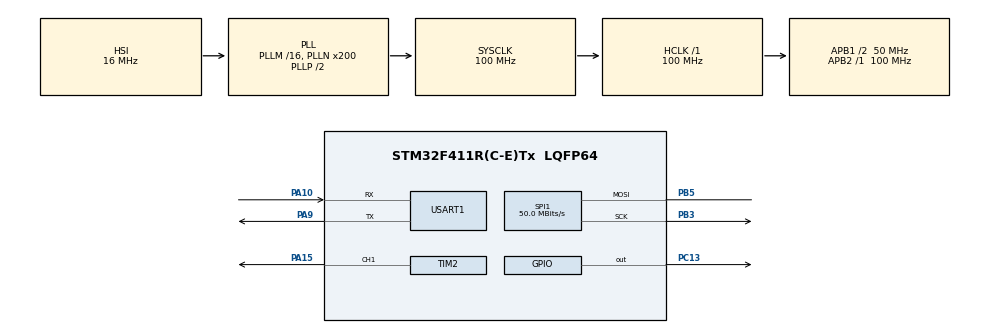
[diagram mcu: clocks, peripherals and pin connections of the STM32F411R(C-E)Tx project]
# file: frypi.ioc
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Dma.Request0=SPI1_TX
Dma.SPI1_TX.0.Direction=DMA_MEMORY_TO_PERIPH
Dma.SPI1_TX.0.FIFOMode=DMA_FIFOMODE_DISABLE
Dma.SPI1_TX.0.Instance=DMA2_Stream2
Dma.SPI1_TX.0.MemDataAlignment=DMA_MDATAALIGN_HALFWORD
Dma.SPI1_TX.0.MemInc=DMA_MINC_ENABLE
Dma.SPI1_TX.0.Mode=DMA_NORMAL
Dma.SPI1_TX.0.PeriphDataAlignment=DMA_PDATAALIGN_HALFWORD
Dma.SPI1_TX.0.PeriphInc=DMA_PINC_DISABLE
Dma.SPI1_TX.0.Priority=DMA_PRIORITY_LOW
FREERTOS.Tasks01=defaultTask,24,128,StartDefaultTask,Default,NULL,Dynamic,NULL,NULL;LED_Task,8,128,LED_TaskFunc,Default,NULL,Static,LED_TaskBuffer,LED_TaskControlBlock
FREERTOS.configUSE_TICK_HOOK=1
Mcu.Family=STM32F4
Mcu.Name=STM32F411R(C-E)Tx
Mcu.Package=LQFP64
NVIC.DMA2_Stream2_IRQn=true\:5\:0\:false\:false\:true\:true\:false\:true\:true
NVIC.PriorityGroup=NVIC_PRIORITYGROUP_4
NVIC.TIM1_TRG_COM_TIM11_IRQn=true\:15\:0\:false\:false\:true\:false\:false\:true\:true
NVIC.TimeBase=TIM1_TRG_COM_TIM11_IRQn
NVIC.TimeBaseIP=TIM11
PA10.Mode=Asynchronous
PA10.Signal=USART1_RX
PA13.Mode=Serial_Wire
PA13.Signal=SYS_JTMS-SWDIO
PA14.Mode=Serial_Wire
PA14.Signal=SYS_JTCK-SWCLK
PA15.Signal=S_TIM2_CH1_ETR
PA9.Mode=Asynchronous
PA9.Signal=USART1_TX
PB3.Mode=Simplex_Bidirectional_Master
PB3.Signal=SPI1_SCK
PB5.Mode=Simplex_Bidirectional_Master
PB5.Signal=SPI1_MOSI
PC13-ANTI_TAMP.Signal=GPIO_Output
ProjectManager.HeapSize=0x200
ProjectManager.StackSize=0x400
ProjectManager.TargetToolchain=CMake
RCC.48MHZClocksFreq_Value=50000000
RCC.AHBFreq_Value=100000000
RCC.APB1CLKDivider=RCC_HCLK_DIV2
RCC.APB1Freq_Value=50000000
RCC.APB1TimFreq_Value=100000000
RCC.APB2Freq_Value=100000000
RCC.APB2TimFreq_Value=100000000
RCC.CortexFreq_Value=100000000
RCC.HCLKFreq_Value=100000000
RCC.HSE_VALUE=25000000
RCC.HSI_VALUE=16000000
RCC.LSE_VALUE=32768
RCC.PLLN=200
RCC.SYSCLKFreq_VALUE=100000000
RCC.SYSCLKSource=RCC_SYSCLKSOURCE_PLLCLK
RCC.VCOOutputFreq_Value=200000000
SH.S_TIM2_CH1_ETR.0=TIM2_CH1,PWM Generation1 CH1
SPI1.CLKPhase=SPI_PHASE_2EDGE
SPI1.CLKPolarity=SPI_POLARITY_HIGH
SPI1.CalculateBaudRate=50.0 MBits/s
SPI1.Direction=SPI_DIRECTION_1LINE
SPI1.Mode=SPI_MODE_MASTER
SPI1.VirtualType=VM_MASTER
TIM2.Channel-PWM\ Generation1\ CH1=TIM_CHANNEL_1
TIM2.Period=300
TIM2.Prescaler=99
USART1.VirtualMode=VM_ASYNC
VP_FREERTOS_VS_CMSIS_V2.Mode=CMSIS_V2
VP_SYS_VS_tim11.Mode=TIM11
board=custom

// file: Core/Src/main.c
/* USER CODE BEGIN Header */
/**
  ******************************************************************************
  * @file           : main.c
  * @brief          : Main program body
  ******************************************************************************
  * @attention
  *
  * Copyright (c) 2026 STMicroelectronics.
  * All rights reserved.
  *
  * This software is licensed under terms that can be found in the LICENSE file
  * in the root directory of this software component.
  * If no LICENSE file comes with this software, it is provided AS-IS.
  *
  ******************************************************************************
  */
/* USER CODE END Header */
#include "main.h"
#include "cmsis_os.h"
#include "dma.h"
#include "spi.h"
#include "tim.h"
#include "usart.h"
#include "gpio.h"

void SystemClock_Config(void);
void MX_FREERTOS_Init(void);

int main(void)
{

  /* MCU Configuration--------------------------------------------------------*/

  /* Reset of all peripherals, Initializes the Flash interface and the Systick. */
  HAL_Init();

  /* Configure the system clock */
  SystemClock_Config();

  /* USER CODE BEGIN SysInit */
  __enable_irq();
  /* USER CODE END SysInit */

  /* Initialize all configured peripherals */
  MX_GPIO_Init();
  MX_DMA_Init();
  MX_USART1_UART_Init();
  MX_SPI1_Init();
  MX_TIM2_Init();

  /* Init scheduler */
  osKernelInitialize();  /* Call init function for freertos objects (in cmsis_os2.c) */
  MX_FREERTOS_Init();

  /* Start scheduler */
  osKernelStart();

  /* We should never get here as control is now taken by the scheduler */

  /* Infinite loop */
  while (1)
  {

  }
}

void SystemClock_Config(void)
{
  RCC_OscInitTypeDef RCC_OscInitStruct = {0};
  RCC_ClkInitTypeDef RCC_ClkInitStruct = {0};

  /** Configure the main internal regulator output voltage
  */
  __HAL_RCC_PWR_CLK_ENABLE();
  __HAL_PWR_VOLTAGESCALING_CONFIG(PWR_REGULATOR_VOLTAGE_SCALE1);

  /** Initializes the RCC Oscillators according to the specified parameters
  * in the RCC_OscInitTypeDef structure.
  */
  RCC_OscInitStruct.OscillatorType = RCC_OSCILLATORTYPE_HSI;
  RCC_OscInitStruct.HSIState = RCC_HSI_ON;
  RCC_OscInitStruct.HSICalibrationValue = RCC_HSICALIBRATION_DEFAULT;
  RCC_OscInitStruct.PLL.PLLState = RCC_PLL_ON;
  RCC_OscInitStruct.PLL.PLLSource = RCC_PLLSOURCE_HSI;
  RCC_OscInitStruct.PLL.PLLM = 16;
  RCC_OscInitStruct.PLL.PLLN = 200;
  RCC_OscInitStruct.PLL.PLLP = RCC_PLLP_DIV2;
  RCC_OscInitStruct.PLL.PLLQ = 4;
  if (HAL_RCC_OscConfig(&RCC_OscInitStruct) != HAL_OK)
  {
    Error_Handler();
  }

  /** Initializes the CPU, AHB and APB buses clocks
  */
  RCC_ClkInitStruct.ClockType = RCC_CLOCKTYPE_HCLK|RCC_CLOCKTYPE_SYSCLK
                              |RCC_CLOCKTYPE_PCLK1|RCC_CLOCKTYPE_PCLK2;
  RCC_ClkInitStruct.SYSCLKSource = RCC_SYSCLKSOURCE_PLLCLK;
  RCC_ClkInitStruct.AHBCLKDivider = RCC_SYSCLK_DIV1;
  RCC_ClkInitStruct.APB1CLKDivider = RCC_HCLK_DIV2;
  RCC_ClkInitStruct.APB2CLKDivider = RCC_HCLK_DIV1;

  if (HAL_RCC_ClockConfig(&RCC_ClkInitStruct, FLASH_LATENCY_3) != HAL_OK)
  {
    Error_Handler();
  }
}

void HAL_TIM_PeriodElapsedCallback(TIM_HandleTypeDef *htim)
{
  if (htim->Instance == TIM11)
  {
    HAL_IncTick();
  }
}

void Error_Handler(void)
{
  __disable_irq();
  while (1)
  {
  }
}

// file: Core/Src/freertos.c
/* USER CODE BEGIN Header */
/**
  ******************************************************************************
  * File Name          : freertos.c
  * Description        : Code for freertos applications
  ******************************************************************************
  * @attention
  *
  * Copyright (c) 2026 STMicroelectronics.
  * All rights reserved.
  *
  * This software is licensed under terms that can be found in the LICENSE file
  * in the root directory of this software component.
  * If no LICENSE file comes with this software, it is provided AS-IS.
  *
  ******************************************************************************
  */
/* USER CODE END Header */

#include "FreeRTOS.h"
#include "task.h"
#include "main.h"
#include "cmsis_os.h"

/* USER CODE BEGIN Includes */
#include <stdio.h>
#include "app.h"
#include "lvgl/src/hal/lv_hal_tick.h"
/* USER CODE END Includes */

typedef StaticTask_t osStaticThreadDef_t;

/* Definitions for defaultTask */
osThreadId_t defaultTaskHandle;
const osThreadAttr_t defaultTask_attributes = {
  .name = "defaultTask",
  .stack_size = 128 * 4,
  .priority = (osPriority_t) osPriorityNormal,
};
/* Definitions for LED_Task */
osThreadId_t LED_TaskHandle;
uint32_t LED_TaskBuffer[ 128 ];
osStaticThreadDef_t LED_TaskControlBlock;
const osThreadAttr_t LED_Task_attributes = {
  .name = "LED_Task",
  .cb_mem = &LED_TaskControlBlock,
  .cb_size = sizeof(LED_TaskControlBlock),
  .stack_mem = &LED_TaskBuffer[0],
  .stack_size = sizeof(LED_TaskBuffer),
  .priority = (osPriority_t) osPriorityLow,
};

void StartDefaultTask(void *argument);
void LED_TaskFunc(void *argument);

void MX_FREERTOS_Init(void); /* (MISRA C 2004 rule 8.1) */

/* Hook prototypes */
void vApplicationTickHook(void);

/* USER CODE BEGIN 3 */
void vApplicationTickHook( void )
{
   /* This function will be called by each tick interrupt if
   configUSE_TICK_HOOK is set to 1 in FreeRTOSConfig.h. User code can be
   added here, but the tick hook is called from an interrupt context, so
   code must not attempt to block, and only the interrupt safe FreeRTOS API
   functions can be used (those that end in FromISR()). */
   lv_tick_inc(1);
}
/* USER CODE END 3 */

void MX_FREERTOS_Init(void) {

  /* Create the thread(s) */
  /* creation of defaultTask */
  defaultTaskHandle = osThreadNew(StartDefaultTask, NULL, &defaultTask_attributes);

  /* creation of LED_Task */
  LED_TaskHandle = osThreadNew(LED_TaskFunc, NULL, &LED_Task_attributes);

  /* USER CODE BEGIN RTOS_THREADS */
  /* add threads, ... */
  app_tasks_init();
  /* USER CODE END RTOS_THREADS */

}

void StartDefaultTask(void *argument)
{
  /* USER CODE BEGIN StartDefaultTask */
  /* Infinite loop */
  for(;;)
  {
    // printf("idle work\r\n");
    osDelay(1);
  }
  /* USER CODE END StartDefaultTask */
}

void LED_TaskFunc(void *argument)
{
  /* USER CODE BEGIN LED_TaskFunc */
  /* Infinite loop */
  for(;;)
  {
    HAL_GPIO_TogglePin(GPIOC, GPIO_PIN_13);
    osDelay(1000);
  }
  /* USER CODE END LED_TaskFunc */
}
